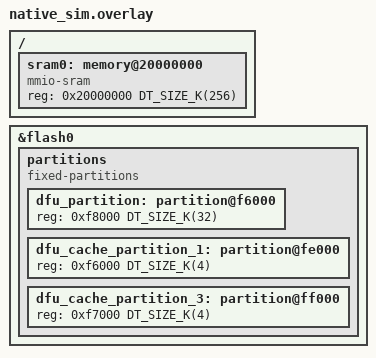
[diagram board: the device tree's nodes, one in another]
/*
 * Copyright (c) 2024 Nordic Semiconductor ASA
 *
 * SPDX-License-Identifier: LicenseRef-Nordic-5-Clause
 */

&flash0 {
	partitions {
		compatible = "fixed-partitions";
		#address-cells = <1>;
		#size-cells = <1>;

		/* Use the last 32KB of NVM as dfu_partition. */
		dfu_partition: partition@f6000 {
			reg = <0xf8000 DT_SIZE_K(32)>;
		};
		dfu_cache_partition_1: partition@fe000 {
			reg = <0xf6000 DT_SIZE_K(4)>;
		};

		dfu_cache_partition_3: partition@ff000 {
			reg = <0xf7000 DT_SIZE_K(4)>;
		};
	};
};

/ {
	sram0: memory@20000000 {
		compatible = "mmio-sram";
		reg = <0x20000000 DT_SIZE_K(256)>;
	};
};
